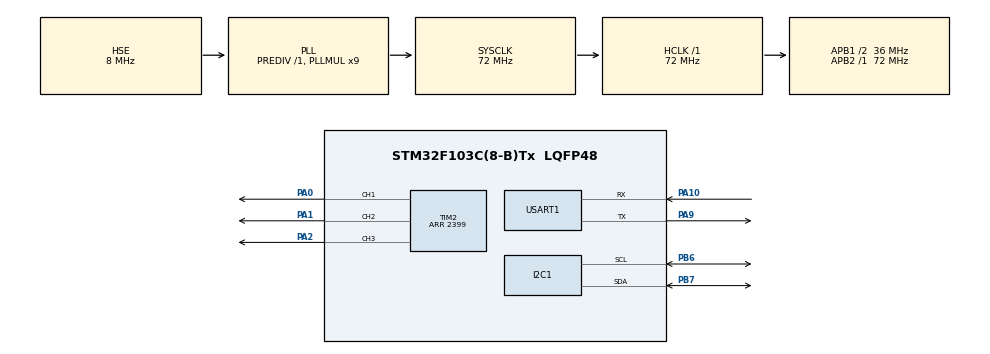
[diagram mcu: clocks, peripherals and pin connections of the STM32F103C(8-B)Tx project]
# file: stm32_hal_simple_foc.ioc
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Dma.I2C1_RX.0.Direction=DMA_PERIPH_TO_MEMORY
Dma.I2C1_RX.0.Instance=DMA1_Channel7
Dma.I2C1_RX.0.MemDataAlignment=DMA_MDATAALIGN_BYTE
Dma.I2C1_RX.0.MemInc=DMA_MINC_ENABLE
Dma.I2C1_RX.0.Mode=DMA_NORMAL
Dma.I2C1_RX.0.PeriphDataAlignment=DMA_PDATAALIGN_BYTE
Dma.I2C1_RX.0.PeriphInc=DMA_PINC_DISABLE
Dma.I2C1_RX.0.Priority=DMA_PRIORITY_LOW
Dma.I2C1_TX.1.Direction=DMA_MEMORY_TO_PERIPH
Dma.I2C1_TX.1.Instance=DMA1_Channel6
Dma.I2C1_TX.1.MemDataAlignment=DMA_MDATAALIGN_BYTE
Dma.I2C1_TX.1.MemInc=DMA_MINC_ENABLE
Dma.I2C1_TX.1.Mode=DMA_NORMAL
Dma.I2C1_TX.1.PeriphDataAlignment=DMA_PDATAALIGN_BYTE
Dma.I2C1_TX.1.PeriphInc=DMA_PINC_DISABLE
Dma.I2C1_TX.1.Priority=DMA_PRIORITY_LOW
Dma.Request0=I2C1_RX
Dma.Request1=I2C1_TX
Mcu.Family=STM32F1
Mcu.Name=STM32F103C(8-B)Tx
Mcu.Package=LQFP48
NVIC.DMA1_Channel6_IRQn=true\:0\:0\:false\:false\:true\:false\:true\:true
NVIC.DMA1_Channel7_IRQn=true\:0\:0\:false\:false\:true\:false\:true\:true
NVIC.I2C1_EV_IRQn=true\:0\:0\:false\:false\:true\:true\:true\:true
NVIC.PriorityGroup=NVIC_PRIORITYGROUP_4
NVIC.USART1_IRQn=true\:0\:0\:false\:false\:true\:true\:true\:true
PA0-WKUP.Signal=S_TIM2_CH1_ETR
PA1.Signal=S_TIM2_CH2
PA10.Mode=Asynchronous
PA10.Signal=USART1_RX
PA2.Signal=S_TIM2_CH3
PA9.Mode=Asynchronous
PA9.Signal=USART1_TX
PB6.Mode=I2C
PB6.Signal=I2C1_SCL
PB7.Mode=I2C
PB7.Signal=I2C1_SDA
PD0-OSC_IN.Mode=HSE-External-Oscillator
PD0-OSC_IN.Signal=RCC_OSC_IN
PD1-OSC_OUT.Mode=HSE-External-Oscillator
PD1-OSC_OUT.Signal=RCC_OSC_OUT
ProjectManager.HeapSize=0x200
ProjectManager.StackSize=0x400
ProjectManager.TargetToolchain=MDK-ARM V5.32
RCC.AHBFreq_Value=72000000
RCC.APB1CLKDivider=RCC_HCLK_DIV2
RCC.APB1Freq_Value=36000000
RCC.APB1TimFreq_Value=72000000
RCC.APB2Freq_Value=72000000
RCC.APB2TimFreq_Value=72000000
RCC.HCLKFreq_Value=72000000
RCC.PLLMUL=RCC_PLL_MUL9
RCC.PLLSourceVirtual=RCC_PLLSOURCE_HSE
RCC.SYSCLKFreq_VALUE=72000000
RCC.SYSCLKSource=RCC_SYSCLKSOURCE_PLLCLK
RCC.USBFreq_Value=72000000
SH.S_TIM2_CH1_ETR.0=TIM2_CH1,PWM Generation1 CH1
SH.S_TIM2_CH2.0=TIM2_CH2,PWM Generation2 CH2
SH.S_TIM2_CH3.0=TIM2_CH3,PWM Generation3 CH3
TIM2.AutoReloadPreload=TIM_AUTORELOAD_PRELOAD_ENABLE
TIM2.Channel-PWM\ Generation1\ CH1=TIM_CHANNEL_1
TIM2.Channel-PWM\ Generation2\ CH2=TIM_CHANNEL_2
TIM2.Channel-PWM\ Generation3\ CH3=TIM_CHANNEL_3
TIM2.Period=2399
TIM2.Pulse-PWM\ Generation1\ CH1=0
USART1.VirtualMode=VM_ASYNC
VP_SYS_VS_ND.Mode=No_Debug
board=custom

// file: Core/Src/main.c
/* USER CODE BEGIN Header */
/**
  ******************************************************************************
  * @file           : main.c
  * @brief          : Main program body
  ******************************************************************************
  * @attention
  *
  * Copyright (c) 2023 STMicroelectronics.
  * All rights reserved.
  *
  * This software is licensed under terms that can be found in the LICENSE file
  * in the root directory of this software component.
  * If no LICENSE file comes with this software, it is provided AS-IS.
  *
  ******************************************************************************
  */
/* USER CODE END Header */
#include "main.h"

/* USER CODE BEGIN Includes */
#include "example_main.h"
/* USER CODE END Includes */

I2C_HandleTypeDef hi2c1;
DMA_HandleTypeDef hdma_i2c1_rx;
DMA_HandleTypeDef hdma_i2c1_tx;

TIM_HandleTypeDef htim2;

UART_HandleTypeDef huart1;

void SystemClock_Config(void);
static void MX_GPIO_Init(void);
static void MX_DMA_Init(void);
static void MX_USART1_UART_Init(void);
static void MX_I2C1_Init(void);
static void MX_TIM2_Init(void);

int main(void)
{

  /* MCU Configuration--------------------------------------------------------*/

  /* Reset of all peripherals, Initializes the Flash interface and the Systick. */
  HAL_Init();

  /* Configure the system clock */
  SystemClock_Config();

  /* Initialize all configured peripherals */
  MX_GPIO_Init();
  MX_DMA_Init();
  MX_USART1_UART_Init();
  MX_I2C1_Init();
  MX_TIM2_Init();
  /* USER CODE BEGIN 2 */
  example_main();
  /* USER CODE END 2 */

  /* Infinite loop */
  while (1)
  {

  }
}

void SystemClock_Config(void)
{
  RCC_OscInitTypeDef RCC_OscInitStruct = {0};
  RCC_ClkInitTypeDef RCC_ClkInitStruct = {0};

  /** Initializes the RCC Oscillators according to the specified parameters
  * in the RCC_OscInitTypeDef structure.
  */
  RCC_OscInitStruct.OscillatorType = RCC_OSCILLATORTYPE_HSE;
  RCC_OscInitStruct.HSEState = RCC_HSE_ON;
  RCC_OscInitStruct.HSEPredivValue = RCC_HSE_PREDIV_DIV1;
  RCC_OscInitStruct.HSIState = RCC_HSI_ON;
  RCC_OscInitStruct.PLL.PLLState = RCC_PLL_ON;
  RCC_OscInitStruct.PLL.PLLSource = RCC_PLLSOURCE_HSE;
  RCC_OscInitStruct.PLL.PLLMUL = RCC_PLL_MUL9;
  if (HAL_RCC_OscConfig(&RCC_OscInitStruct) != HAL_OK)
  {
    Error_Handler();
  }

  /** Initializes the CPU, AHB and APB buses clocks
  */
  RCC_ClkInitStruct.ClockType = RCC_CLOCKTYPE_HCLK|RCC_CLOCKTYPE_SYSCLK
                              |RCC_CLOCKTYPE_PCLK1|RCC_CLOCKTYPE_PCLK2;
  RCC_ClkInitStruct.SYSCLKSource = RCC_SYSCLKSOURCE_PLLCLK;
  RCC_ClkInitStruct.AHBCLKDivider = RCC_SYSCLK_DIV1;
  RCC_ClkInitStruct.APB1CLKDivider = RCC_HCLK_DIV2;
  RCC_ClkInitStruct.APB2CLKDivider = RCC_HCLK_DIV1;

  if (HAL_RCC_ClockConfig(&RCC_ClkInitStruct, FLASH_LATENCY_2) != HAL_OK)
  {
    Error_Handler();
  }
}

static void MX_I2C1_Init(void)
{

  hi2c1.Instance = I2C1;
  hi2c1.Init.ClockSpeed = 100000;
  hi2c1.Init.DutyCycle = I2C_DUTYCYCLE_2;
  hi2c1.Init.OwnAddress1 = 0;
  hi2c1.Init.AddressingMode = I2C_ADDRESSINGMODE_7BIT;
  hi2c1.Init.DualAddressMode = I2C_DUALADDRESS_DISABLE;
  hi2c1.Init.OwnAddress2 = 0;
  hi2c1.Init.GeneralCallMode = I2C_GENERALCALL_DISABLE;
  hi2c1.Init.NoStretchMode = I2C_NOSTRETCH_DISABLE;
  if (HAL_I2C_Init(&hi2c1) != HAL_OK)
  {
    Error_Handler();
  }

}

static void MX_TIM2_Init(void)
{

  TIM_MasterConfigTypeDef sMasterConfig = {0};
  TIM_OC_InitTypeDef sConfigOC = {0};

  htim2.Instance = TIM2;
  htim2.Init.Prescaler = 0;
  htim2.Init.CounterMode = TIM_COUNTERMODE_UP;
  htim2.Init.Period = 2399;
  htim2.Init.ClockDivision = TIM_CLOCKDIVISION_DIV1;
  htim2.Init.AutoReloadPreload = TIM_AUTORELOAD_PRELOAD_ENABLE;
  if (HAL_TIM_PWM_Init(&htim2) != HAL_OK)
  {
    Error_Handler();
  }
  sMasterConfig.MasterOutputTrigger = TIM_TRGO_RESET;
  sMasterConfig.MasterSlaveMode = TIM_MASTERSLAVEMODE_DISABLE;
  if (HAL_TIMEx_MasterConfigSynchronization(&htim2, &sMasterConfig) != HAL_OK)
  {
    Error_Handler();
  }
  sConfigOC.OCMode = TIM_OCMODE_PWM1;
  sConfigOC.Pulse = 0;
  sConfigOC.OCPolarity = TIM_OCPOLARITY_HIGH;
  sConfigOC.OCFastMode = TIM_OCFAST_DISABLE;
  if (HAL_TIM_PWM_ConfigChannel(&htim2, &sConfigOC, TIM_CHANNEL_1) != HAL_OK)
  {
    Error_Handler();
  }
  if (HAL_TIM_PWM_ConfigChannel(&htim2, &sConfigOC, TIM_CHANNEL_2) != HAL_OK)
  {
    Error_Handler();
  }
  if (HAL_TIM_PWM_ConfigChannel(&htim2, &sConfigOC, TIM_CHANNEL_3) != HAL_OK)
  {
    Error_Handler();
  }
  HAL_TIM_MspPostInit(&htim2);

}

static void MX_USART1_UART_Init(void)
{

  huart1.Instance = USART1;
  huart1.Init.BaudRate = 115200;
  huart1.Init.WordLength = UART_WORDLENGTH_8B;
  huart1.Init.StopBits = UART_STOPBITS_1;
  huart1.Init.Parity = UART_PARITY_NONE;
  huart1.Init.Mode = UART_MODE_TX_RX;
  huart1.Init.HwFlowCtl = UART_HWCONTROL_NONE;
  huart1.Init.OverSampling = UART_OVERSAMPLING_16;
  if (HAL_UART_Init(&huart1) != HAL_OK)
  {
    Error_Handler();
  }

}

static void MX_DMA_Init(void)
{

  /* DMA controller clock enable */
  __HAL_RCC_DMA1_CLK_ENABLE();

  /* DMA interrupt init */
  /* DMA1_Channel6_IRQn interrupt configuration */
  HAL_NVIC_SetPriority(DMA1_Channel6_IRQn, 0, 0);
  HAL_NVIC_EnableIRQ(DMA1_Channel6_IRQn);
  /* DMA1_Channel7_IRQn interrupt configuration */
  HAL_NVIC_SetPriority(DMA1_Channel7_IRQn, 0, 0);
  HAL_NVIC_EnableIRQ(DMA1_Channel7_IRQn);

}

static void MX_GPIO_Init(void)
{

  /* GPIO Ports Clock Enable */
  __HAL_RCC_GPIOD_CLK_ENABLE();
  __HAL_RCC_GPIOA_CLK_ENABLE();
  __HAL_RCC_GPIOB_CLK_ENABLE();

}

void Error_Handler(void)
{
  __disable_irq();
  while (1)
  {
  }
}
